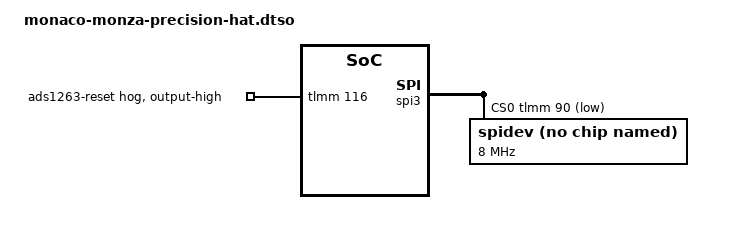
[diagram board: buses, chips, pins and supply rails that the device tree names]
// SPDX-License-Identifier: BSD-3-Clause
/*
 * Copyright (c) Qualcomm Technologies, Inc. and/or its subsidiaries.
 *
 * Device tree overlay for the Waveshare High-Precision AD HAT (ADS1263)
 * connected to the Monza 40-pin JHAT connector.
 */
/dts-v1/;
/plugin/;

#include <dt-bindings/gpio/gpio.h>

&spi3 {
	#address-cells = <1>;
	#size-cells = <0>;
	cs-gpios = <&tlmm 90 GPIO_ACTIVE_LOW>;

	spidev@0 {
		compatible = "rohm,dh2228fv";
		reg = <0>;
		spi-max-frequency = <8000000>;
		spi-cpha;
	};
};

&tlmm {
	ads1263_reset_hog: ads1263-reset-hog {
		gpio-hog;
		gpios = <116 GPIO_ACTIVE_HIGH>;
		output-high;
		line-name = "ads1263-reset";
	};
};
